CM_ "AUTOGENERATED FILE, DO NOT EDIT"

VERSION ""

NS_ :

BS_:

BU_: EBCM EON CAM RADAR PCM EPS VSA SCM BDY XXX EPB EO E

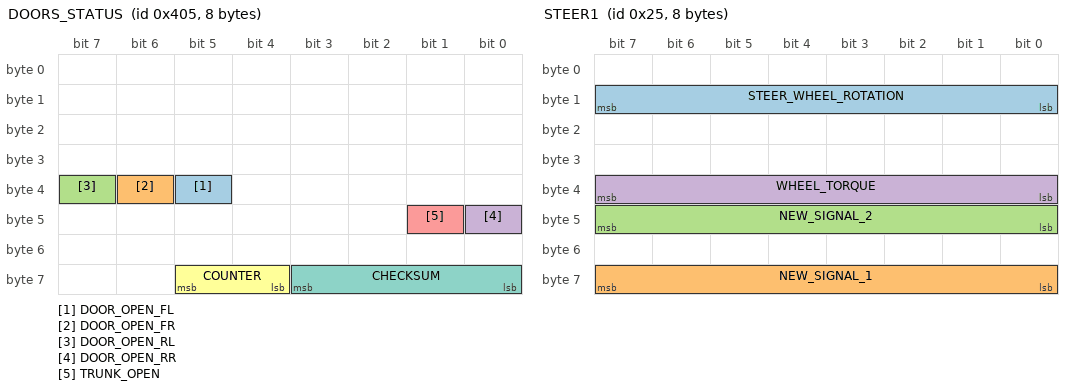
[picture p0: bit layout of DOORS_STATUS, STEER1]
BO_ 1029 DOORS_STATUS: 8 BDY
 SG_ DOOR_OPEN_FL : 37|1@0+ (1,0) [0|1] "" EON
 SG_ DOOR_OPEN_FR : 38|1@0+ (1,0) [0|1] "" EON
 SG_ DOOR_OPEN_RL : 39|1@0+ (1,0) [0|1] "" EON
 SG_ DOOR_OPEN_RR : 40|1@0+ (1,0) [0|1] "" EON
 SG_ TRUNK_OPEN : 41|1@0+ (1,0) [0|1] "" EON
 SG_ COUNTER : 61|2@0+ (1,0) [0|3] "" EON
 SG_ CHECKSUM : 59|4@0+ (1,0) [0|15] "" EON

BO_ 37 STEER1: 8 XXX
 SG_ STEER_WHEEL_ROTATION : 8|8@1- (1,0) [0|255] "" XXX
 SG_ NEW_SIGNAL_1 : 56|8@1+ (1,0) [0|255] "" XXX
 SG_ NEW_SIGNAL_2 : 40|8@1+ (1,0) [0|255] "" XXX
 SG_ WHEEL_TORQUE : 39|8@0+ (-1,130) [0|255] "" XXX

BO_ 1569 LOCK_COMMAND: 8 XXX
 SG_ ACTUATOR_COMMAND : 15|1@0+ (1,0) [0|1] "" XXX
 SG_ LOCK_ACTION : 23|8@0+ (1,0) [0|255] "" XXX

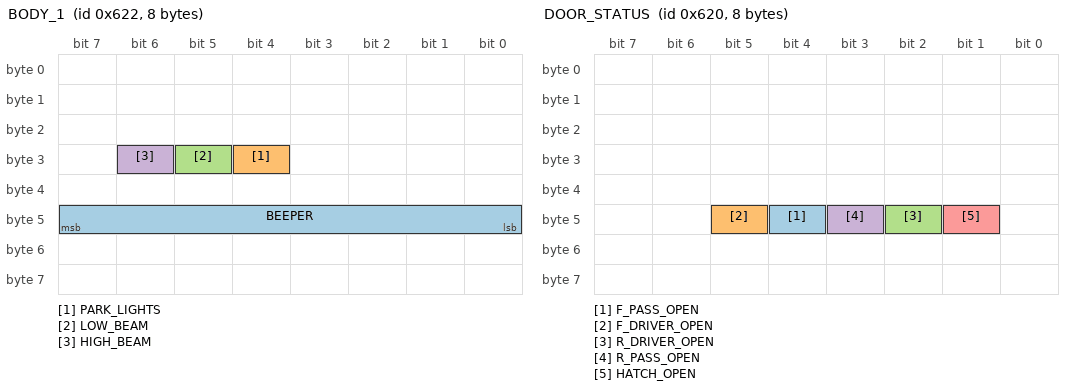
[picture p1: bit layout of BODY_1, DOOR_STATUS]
BO_ 1570 BODY_1: 8 XXX
 SG_ BEEPER : 47|8@0+ (1,0) [0|255] "" XXX
 SG_ PARK_LIGHTS : 28|1@0+ (1,0) [0|1] "" XXX
 SG_ LOW_BEAM : 29|1@0+ (1,0) [0|1] "" XXX
 SG_ HIGH_BEAM : 30|1@0+ (1,0) [0|1] "" XXX

BO_ 1568 DOOR_STATUS: 8 XXX
 SG_ F_PASS_OPEN : 44|1@0+ (1,0) [0|1] "" XXX
 SG_ F_DRIVER_OPEN : 45|1@0+ (1,0) [0|1] "" XXX
 SG_ R_DRIVER_OPEN : 42|1@0+ (1,0) [0|1] "" XXX
 SG_ R_PASS_OPEN : 43|1@0+ (1,0) [0|1] "" XXX
 SG_ HATCH_OPEN : 41|1@0+ (1,0) [0|1] "" XXX

BO_ 1592 LOCK_STATUS: 8 XXX
 SG_ ACTUATOR_REQUEST : 15|1@0+ (1,0) [0|1] "" XXX
 SG_ LOCKS : 20|5@0+ (1,0) [0|31] "" XXX

BO_ 176 SPEED2: 8 XXX
 SG_ WHEEL_SPEED1 : 7|16@0+ (0.01,0) [0|65535] "kph" XXX
 SG_ WHEEL_SPEED2 : 23|16@0+ (0.01,0) [0|65535] "KPH" XXX

BO_ 548 BRAKE1: 8 XXX
 SG_ USER_BRAKE : 40|8@1+ (1,0) [0|255] "" XXX

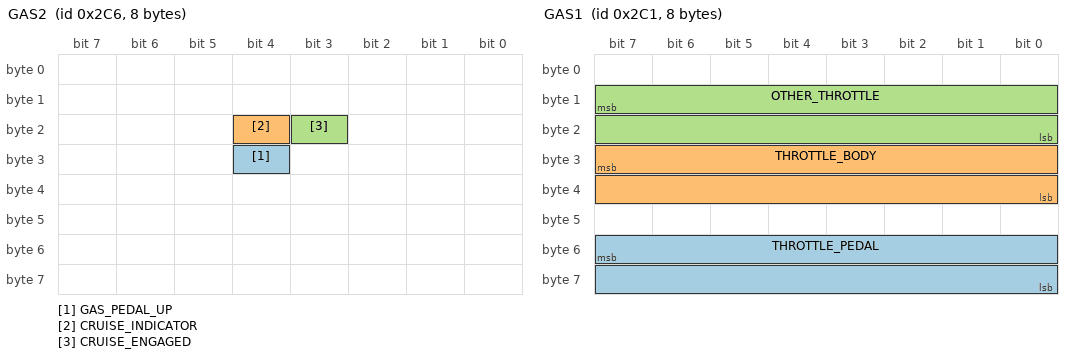
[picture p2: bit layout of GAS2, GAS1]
BO_ 710 GAS2: 8 XXX
 SG_ GAS_PEDAL_UP : 28|1@0+ (1,0) [0|1] "" XXX
 SG_ CRUISE_INDICATOR : 20|1@0+ (1,0) [0|1] "" XXX
 SG_ CRUISE_ENGAGED : 19|1@0+ (1,0) [0|1] "" XXX

BO_ 705 GAS1: 8 XXX
 SG_ THROTTLE_PEDAL : 55|16@0+ (1,0) [0|65535] "" XXX
 SG_ THROTTLE_BODY : 31|16@0+ (1,0) [0|65535] "" XXX
 SG_ OTHER_THROTTLE : 15|16@0+ (1,0) [0|65535] "" XXX

BO_ 720 GEARBOX1: 8 XXX
 SG_ GEAR2 : 24|4@1+ (1,0) [0|255] "" XXX
 SG_ GEAR1 : 16|5@1+ (1,0) [0|255] "" XXX

BO_ 708 NEW_MSG_1: 8 XXX
 SG_ RPM : 7|16@0+ (1,0) [0|65535] "" XXX

BO_ 178 SPEED1: 8 XXX
 SG_ WHEEL_SPEED2 : 23|16@0+ (0.01,0) [0|65535] "kph" XXX
 SG_ WHEEL_SPEED1 : 7|16@0+ (0.01,0) [0|65535] "KPH" XXX

CM_ SG_ 1569 LOCK_ACTION "169=DRIVER UNLOCK, 161=OTHER UNLOCK, 33=LOCKALL";
CM_ SG_ 1570 BEEPER "17=SINGLE BEEP, 33 DOUBLE BEEP, 239=CONTINUOUS";
CM_ SG_ 720 GEAR2 "0 = NA, 8 = D, 5 = 3, 2 = 2, 1 = L";
CM_ SG_ 720 GEAR1 "P = 9, R = 2, N = 0C, D=10, 0=NA";
